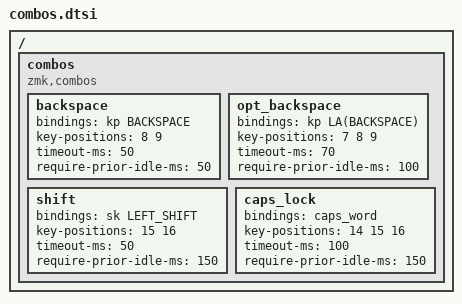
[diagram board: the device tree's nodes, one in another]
/*                                      42 KEY MATRIX / LAYOUT MAPPING

  ╭────────────────────────┬────────────────────────╮
  │  0   1   2   3   4   5 │  6   7   8   9  10  11 │
  │ 12  13  14  15  16  17 │ 18  19  20  21  22  23 │
  │ 24  25  26  27  28  29 │ 30  31  32  33  34  35 │
  ╰───────────╮ 36  37  38 │ 39  40  41 ╭───────────╯
              ╰────────────┴────────────╯              */


/ {

    combos {
        compatible = "zmk,combos";

        backspace {
            bindings = <&kp BACKSPACE>;
            key-positions = <8 9>;
            timeout-ms = <50>;
            require-prior-idle-ms = <50>;
        };

        opt_backspace {
            bindings = <&kp LA(BACKSPACE)>;
            key-positions = <7 8 9>;
            timeout-ms = <70>;
            require-prior-idle-ms = <100>;
        };

        shift {
            bindings = <&sk LEFT_SHIFT>;
            key-positions = <15 16>;
            timeout-ms = <50>;
            require-prior-idle-ms = <150>;
        };

        caps_lock {
            bindings = <&caps_word>;
            key-positions = <14 15 16>;
            timeout-ms = <100>;
            require-prior-idle-ms = <150>;
        };
    };
};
